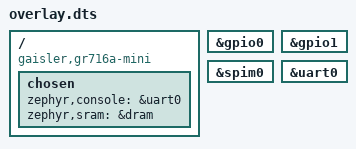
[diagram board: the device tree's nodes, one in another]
/ {
	compatible = "gaisler,gr716a-mini";
	chosen {
		zephyr,console = &uart0;
		zephyr,sram = &dram;
	};
};
&gpio0{
	status = "okay";
};
&gpio1{
	status = "okay";
};
&spim0{
	status = "okay";
};
&uart0{
	status = "okay";
};
